# RL6842_IP_SVD register map
Vendor: Realtek
Registers are 32-bit, read-write, reset 0x0 unless marked. A register's access mark holds for its fields unless they carry their own. Offsets are from the block's base; [hi:lo] are bit positions; {n}, {i} and the like mark numbered series.

## PLL
Base 0x4100C440
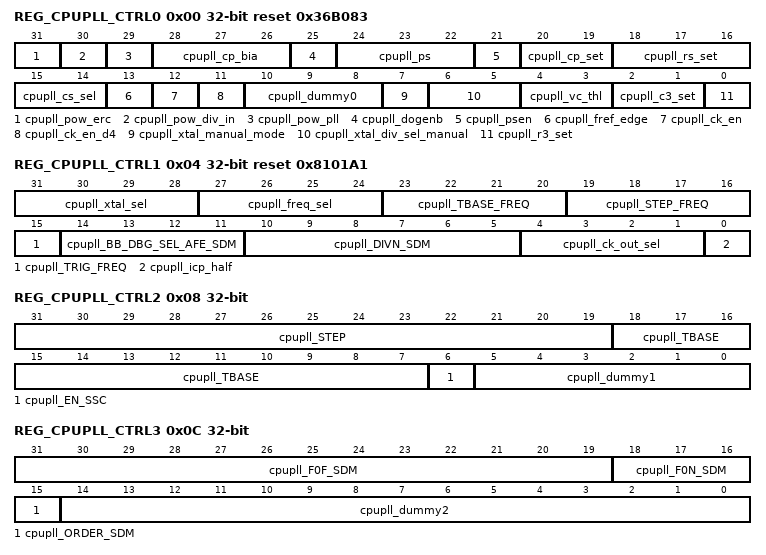
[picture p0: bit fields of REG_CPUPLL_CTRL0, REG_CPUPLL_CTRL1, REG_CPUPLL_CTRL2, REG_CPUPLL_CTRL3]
0x00 REG_CPUPLL_CTRL0 reset 0x36B083
  [31] cpupll_pow_erc — erc enable. 0 -> 1
  [30] cpupll_pow_div_in — input divider enable (need pwl signal) 0 -> 1
  [29] cpupll_pow_pll — (need pwl signal) 0 -> 1
  [28:26] cpupll_cp_bia — charge pump current selection . Default=10uA CP current select : 000: Icp=10uA, 001: Icp=15uA, 010: Icp=20uA, 011: Icp=25uA; 100: Icp=30uA, 101: Icp=35uA, 110: Icp=40uA, 111: Icp=450uA;
  [25] cpupll_dogenb — 0: watch dog on, 1: watch dog off
  [24:22] cpupll_ps
  [21] cpupll_psen — phase selector enable
  [20:19] cpupll_cp_set — Cp selection. Default=6p 00: Cp=4p, 01: Cp=5p, 10: Cp=6p, 11: Cp=7p 40M = 6p(10), 26M = 6p(10)
  [18:16] cpupll_rs_set — Rs selection. Default=5k 000: Rs=15k, 001: Rs=13k, 010: Rs=11k, 011: Rs=9k, 100: Rs=7k, 101: Rs=5k, 110: Rs=3k, 111: Rs=1k; 40M = 5k(101), 26M = 5k(101)
  [15:14] cpupll_cs_sel — Cs selection. Default=60p 00: Cs=40p, 01: Cs=50p, 10: Cs=60p, 11: Cs=70p 40M = 60p(10), 26M = 60p(10)
  [13] cpupll_fref_edge — 0:fref, 1:frefb
  [12] cpupll_ck_en — output clk enable
  [11] cpupll_ck_en_d4 — output clk div 4 enable
  [10:8] cpupll_dummy0
  [7] cpupll_xtal_manual_mode — reg_xtal_maunal_mode. Default=0 0: reg_xtal_sel<3:0> is controlled by REG, xtal_div_sel is controlled by mapping table. 1: reg_xtal_sel<3:0>=4'b1111, xtal_div_sel is controlled by reg_xtal_div_sel_maunal<1:0>
  [6:5] cpupll_xtal_div_sel_manual — input divider selection in xtal maunal mode. Default=00 00=/1, 10=/2, 11=/4
  [4:3] cpupll_vc_thl — VC voltage, Default=00 00: VC=1/4Vdd, 01: VC=1/2Vdd, 10=3/4Vdd, 11: VC=Vdd
  [2:1] cpupll_c3_set — C3 selection. Default=1p 00: 0.5p, 01: 1p, 10: Cs=1.5p, 11: 2p
  [0] cpupll_r3_set — Rs selection. Default=1k 0: 0 Ohm, 1: 1k Ohm
0x04 REG_CPUPLL_CTRL1 reset 0x8101A1
  [31:28] cpupll_xtal_sel — xtal selection, Default=40MHz 0000= 40MHz, 0001= 25MHz, 0010= 13MHz, 0011= 19.2MHz 0100= 20MHz, 0101= 26MHz, 0110= 38.4MHz, 0111= 17.664MHz 1000= 16MHz, 1001= 14.138MHz, 1010= 12MHz, 1011= 52MHz 1100= 48MHz, 1101= 27MHz, 1110= 24MHz, 1111= none
  [27:24] cpupll_freq_sel — output clk selection, Default=400MHz 0000= 400MHz, 0001= X, 0010= X, 0011= X, 0100= 216MHz, 0101=196.608MHz, 0110=192MHz, 0111= 180.632MHz, 1000= 148.5MHz,1001= X, 1010= X, 1011= X, 1100= X, 1101= X, 1110= X, 1111= 500MHz
  [23:20] cpupll_TBASE_FREQ — now is empty
  [19:16] cpupll_STEP_FREQ — step size selection for switching freq. 0000: 2^5 0001: 2^6 0010: 2^7 0011: 2^8 0100: 2^9 0101: 2^10 0110: 2^11 0111: 2^12
  [15] cpupll_TRIG_FREQ — freq. step up or step down enable
  [14:11] cpupll_BB_DBG_SEL_AFE_SDM
  [10:5] cpupll_DIVN_SDM — 393.216M (98.304M / 24.576M) 40M: 000111 26M: 001101
  [4:1] cpupll_ck_out_sel — output divider selection. Default=1110(/16) 0000=/1, 1000=/2, 1100=/8, 1110=/16, 1111=/32
  [0] cpupll_icp_half — charge pump current half or not 0: no half 1: half
0x08 REG_CPUPLL_CTRL2
  [31:19] cpupll_STEP — ssc step size selection.
  [18:7] cpupll_TBASE — ssc freq selection
  [6] cpupll_EN_SSC — ssc enable. Default=0
  [5:0] cpupll_dummy1 — HW used only , these are for reserved
0x0C REG_CPUPLL_CTRL3
  [31:19] cpupll_F0F_SDM — 393.216M (98.304M / 24.576M) 40M: 1 0100 1001 0101 26M: 1 1111 1010 1010
  [18:16] cpupll_F0N_SDM — 393.216M (98.304M / 24.576M) 40M: 110 26M: 000
  [15] cpupll_ORDER_SDM — SDM order
  [14:0] cpupll_dummy2 — HW used only , these are for reserved
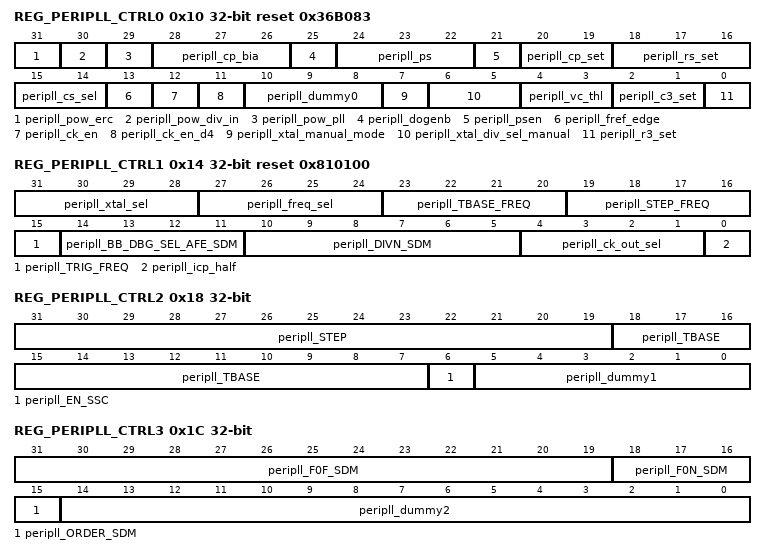
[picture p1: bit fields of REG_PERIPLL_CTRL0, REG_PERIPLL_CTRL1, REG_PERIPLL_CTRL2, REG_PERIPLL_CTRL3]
0x10 REG_PERIPLL_CTRL0 reset 0x36B083
  [31] peripll_pow_erc — erc enable. 0 -> 1
  [30] peripll_pow_div_in — input divider enable (need pwl signal) 0 -> 1
  [29] peripll_pow_pll — (need pwl signal) 0 -> 1
  [28:26] peripll_cp_bia — charge pump current selection . Default=10uA CP current select : 000: Icp=10uA, 001: Icp=15uA, 010: Icp=20uA, 011: Icp=25uA; 100: Icp=30uA, 101: Icp=35uA, 110: Icp=40uA, 111: Icp=450uA;
  [25] peripll_dogenb — 0: watch dog on, 1: watch dog off
  [24:22] peripll_ps
  [21] peripll_psen — phase selector enable
  [20:19] peripll_cp_set — Cp selection. Default=6p 00: Cp=4p, 01: Cp=5p, 10: Cp=6p, 11: Cp=7p 40M = 6p(10), 26M = 6p(10)
  [18:16] peripll_rs_set — Rs selection. Default=5k 000: Rs=15k, 001: Rs=13k, 010: Rs=11k, 011: Rs=9k, 100: Rs=7k, 101: Rs=5k, 110: Rs=3k, 111: Rs=1k; 40M = 3k(110), 26M = 3k(110)
  [15:14] peripll_cs_sel — Cs selection. Default=60p 00: Cs=40p, 01: Cs=50p, 10: Cs=60p, 11: Cs=70p 40M = 60p(10), 26M = 60p(10)
  [13] peripll_fref_edge — 0:fref, 1:frefb
  [12] peripll_ck_en — output clk enable
  [11] peripll_ck_en_d4 — output clk div 4 enable
  [10:8] peripll_dummy0
  [7] peripll_xtal_manual_mode — reg_xtal_maunal_mode. Default=0 0: reg_xtal_sel<3:0> is controlled by REG, xtal_div_sel is controlled by mapping table. 1: reg_xtal_sel<3:0>=4'b1111, xtal_div_sel is controlled by reg_xtal_div_sel_maunal<1:0>
  [6:5] peripll_xtal_div_sel_manual — input divider selection in xtal maunal mode. Default=00 00=/1, 10=/2, 11=/4
  [4:3] peripll_vc_thl — VC voltage, Default=00 00: VC=1/4Vdd, 01: VC=1/2Vdd, 10=3/4Vdd, 11: VC=Vdd
  [2:1] peripll_c3_set — C3 selection. Default=1p 00: 0.5p, 01: 1p, 10: Cs=1.5p, 11: 2p
  [0] peripll_r3_set — Rs selection. Default=1k 0: 0 Ohm, 1: 1k Ohm
0x14 REG_PERIPLL_CTRL1 reset 0x810100
  [31:28] peripll_xtal_sel — xtal selection, Default=40MHz 0000= 40MHz, 0001= 25MHz, 0010= 13MHz, 0011= 19.2MHz 0100= 20MHz, 0101= 26MHz, 0110= 38.4MHz, 0111= 17.664MHz 1000= 16MHz, 1001= 14.138MHz, 1010= 12MHz, 1011= 52MHz 1100= 48MHz, 1101= 27MHz, 1110= 24MHz, 1111= none
  [27:24] peripll_freq_sel — output clk selection, Default=400MHz 0000= 400MHz, 0001= X, 0010= X, 0011= X, 0100= 216MHz, 0101=196.608MHz, 0110=192MHz, 0111= 180.632MHz, 1000= 148.5MHz,1001= X, 1010= X, 1011= X, 1100= X, 1101= X, 1110= X, 1111= 500MHz
  [23:20] peripll_TBASE_FREQ — now is empty
  [19:16] peripll_STEP_FREQ — step size selection for switching freq. 0000: 2^5 0001: 2^6 0010: 2^7 0011: 2^8 0100: 2^9 0101: 2^10 0110: 2^11 0111: 2^12
  [15] peripll_TRIG_FREQ — freq. step up or step down enable
  [14:11] peripll_BB_DBG_SEL_AFE_SDM
  [10:5] peripll_DIVN_SDM — 1000M
  [4:1] peripll_ck_out_sel — output divider selection. Default=0000(/1) 0000=/1, 1000=/2, 1100=/8, 1110=/16, 1111=/32
  [0] peripll_icp_half — charge pump current half or not 0: no half 1: half
0x18 REG_PERIPLL_CTRL2
  [31:19] peripll_STEP — ssc step size selection.
  [18:7] peripll_TBASE — ssc freq selection
  [6] peripll_EN_SSC — ssc enable. Default=0
  [5:0] peripll_dummy1 — HW used only , these are for reserved
0x1C REG_PERIPLL_CTRL3
  [31:19] peripll_F0F_SDM — 600M 40M: 0 0000 0000 0000 26M: 1 0011 1011 0001
  [18:16] peripll_F0N_SDM — 600M 40M: 000 26M: 000
  [15] peripll_ORDER_SDM — SDM order
  [14:0] peripll_dummy2 — HW used only , these are for reserved
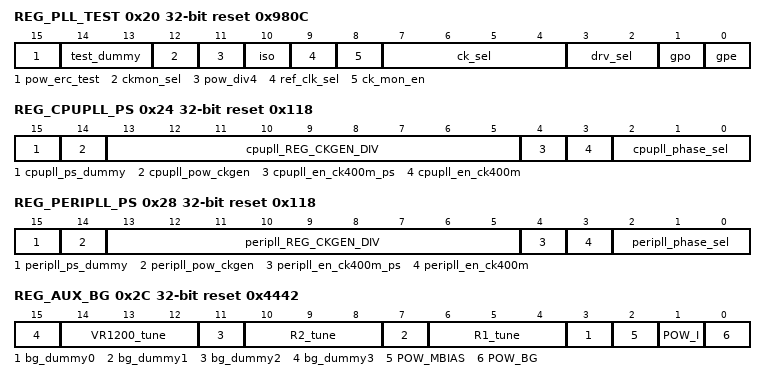
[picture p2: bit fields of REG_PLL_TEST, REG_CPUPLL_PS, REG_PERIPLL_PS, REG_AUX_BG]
0x20 REG_PLL_TEST reset 0x980C
  [15] pow_erc_test — 1 for enable test, 0 for disable
  [14:13] test_dummy — dummy
  [12] ckmon_sel — 0 for CKMON, 1 for CKMOND div by 4
  [11] pow_div4 — 1 for ckmon div 4 , 0 for disable div 4
  [10] iso — 1 for ISO ck_fref/ck_frefb
  [9] ref_clk_sel — xtal clk from 0 special route 1 APR
  [8] ck_mon_en — ckmon enable
  [7:4] ck_sel — ckmon clk sel 1111:TL 1110:TL 1101:CK_400M_CPU_I 1100:CK_CPUD4_I 1011:CK_500M_PERI_I 1010:CK_PERID4_I 1001:TL 1000:READY_CPU_I 0111:READY_PERI_I 0110:TL 0101:TL 0100:TL 0011:TL 0010:TL 0001:TL 0000:TL
  [3:2] drv_sel — AGPIO driving sel
  [1] gpo — AGPIO output enable
  [0] gpe — AGPIO enable
0x24 REG_CPUPLL_PS reset 0x118
  [15] cpupll_ps_dummy — HW used only , these are for reserved
  [14] cpupll_pow_ckgen — pow of ckgen
  [13:5] cpupll_REG_CKGEN_DIV — DIV9B , N=DIV<8:0>+2
  [4] cpupll_en_ck400m_ps
  [3] cpupll_en_ck400m
  [2:0] cpupll_phase_sel
0x28 REG_PERIPLL_PS reset 0x118
  [15] peripll_ps_dummy — HW used only , these are for reserved
  [14] peripll_pow_ckgen — pow of ckgen
  [13:5] peripll_REG_CKGEN_DIV — DIV9B , N=DIV<8:0>+2
  [4] peripll_en_ck400m_ps
  [3] peripll_en_ck400m
  [2:0] peripll_phase_sel
0x2C REG_AUX_BG reset 0x4442
  [4n+3] bg_dummy{n} (n=0..3) — HW used only , these are for reserved
  [14:12] VR1200_tune — Add 40k per step fine tune BG (Efuse)
  [10:8] R2_tune — Add 20k per step fine tune BG (Efuse)
  [6:4] R1_tune — Add 200k per step fine tune BG (Efuse)
  [2] POW_MBIAS — power on mbias
  [1] POW_I — power on BG current
  [0] POW_BG — power on BG
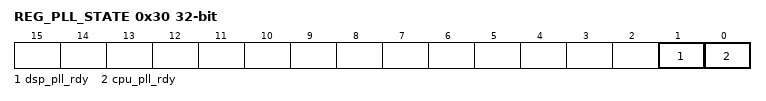
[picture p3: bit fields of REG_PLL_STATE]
0x30 REG_PLL_STATE ro
  [1] dsp_pll_rdy — PERI PLL clock is ready
  [0] cpu_pll_rdy — CPU PLL clock is ready
0x34 PLL_DUMMY reset 0xFF
  [15:0] dummy — HW used only , these are for reserved
